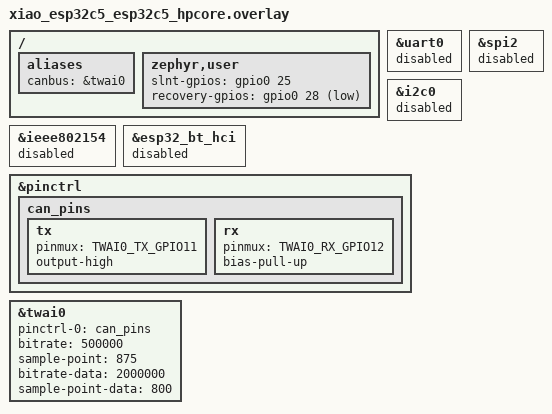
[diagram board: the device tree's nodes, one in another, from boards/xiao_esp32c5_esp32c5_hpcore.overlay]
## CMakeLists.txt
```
cmake_minimum_required(VERSION 3.20.0)
find_package(Zephyr REQUIRED HINTS $ENV{ZEPHYR_BASE})
project(wireless_can)
if(NOT EXISTS ${CMAKE_CURRENT_SOURCE_DIR}/credentials/device_credentials.h)
  message(FATAL_ERROR "Run tools/provision.py before building; there are no universal credentials")
endif()
target_include_directories(app PRIVATE credentials src)
target_sources(app PRIVATE src/main.c src/wire.c src/capture.c src/network.c src/wifi_config.c)
```

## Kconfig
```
mainmenu "Wireless CAN tool"
source "Kconfig.zephyr"
config WCAN_RX_DEPTH
    int "Internal RAM receive records"
    default 128
    range 16 1024
config WCAN_SLNT
    bool "GPIO25 connected to CAN Pal SLNT"
    default y
config WCAN_TX_EVENT_DEPTH
    int "TX outcome queue depth"
    default 32
    range 4 128
```

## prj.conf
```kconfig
CONFIG_GPIO=y
CONFIG_CAN=y
CONFIG_CAN_STATS=y
CONFIG_STATS=y
CONFIG_CAN_FD_MODE=y
CONFIG_CAN_ACCEPT_RTR=y
CONFIG_CAN_MANUAL_RECOVERY_MODE=y
CONFIG_CAN_RX_TIMESTAMP=n
CONFIG_WIFI=y
CONFIG_NETWORKING=y
CONFIG_NET_IPV4=y
CONFIG_NET_IPV6=n
CONFIG_NET_TCP=y
CONFIG_NET_UDP=y
CONFIG_NET_DHCPV4=y
CONFIG_NET_DHCPV4_SERVER=y
CONFIG_NET_MGMT=y
CONFIG_NET_MGMT_EVENT=y
CONFIG_NET_SOCKETS=y
CONFIG_NET_SOCKETS_SOCKOPT_TLS=y
CONFIG_NET_SOCKETS_TLS_MAX_CONTEXTS=2
CONFIG_NET_HOSTNAME_ENABLE=y
CONFIG_NET_HOSTNAME_DYNAMIC=y
CONFIG_NET_HOSTNAME="can-tool"
CONFIG_DNS_SD=y
CONFIG_MDNS_RESPONDER=y
CONFIG_MDNS_RESPONDER_DNS_SD=y
CONFIG_NET_BUF_RX_COUNT=32
CONFIG_NET_BUF_TX_COUNT=32
CONFIG_NET_PKT_RX_COUNT=16
CONFIG_NET_PKT_TX_COUNT=16
CONFIG_NET_MAX_CONTEXTS=10
CONFIG_MBEDTLS=y
CONFIG_MBEDTLS_PEM_PARSE_C=y
CONFIG_MBEDTLS_ENABLE_HEAP=y
CONFIG_MBEDTLS_HEAP_SIZE=60000
CONFIG_MBEDTLS_SSL_IN_CONTENT_LEN=4096
CONFIG_MBEDTLS_SSL_OUT_CONTENT_LEN=4096
CONFIG_MBEDTLS_CIPHERSUITE_TLS_ECDHE_ECDSA_WITH_AES_128_GCM_SHA256=y
CONFIG_TLS_CREDENTIALS=y
CONFIG_SETTINGS=y
CONFIG_SETTINGS_NVS=y
CONFIG_NVS=y
CONFIG_FLASH=y
CONFIG_FLASH_MAP=y
CONFIG_FLASH_PAGE_LAYOUT=y
CONFIG_ENTROPY_GENERATOR=y
CONFIG_TEST_RANDOM_GENERATOR=n
CONFIG_MAIN_STACK_SIZE=8192
CONFIG_SYSTEM_WORKQUEUE_STACK_SIZE=4096
CONFIG_HEAP_MEM_POOL_SIZE=56000
CONFIG_LOG=y
CONFIG_LOG_DEFAULT_LEVEL=2
CONFIG_REBOOT=y
CONFIG_ESP_SPIRAM=n

CONFIG_STACK_SENTINEL=y
```

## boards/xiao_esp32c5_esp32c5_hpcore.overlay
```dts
#include <zephyr/dt-bindings/pinctrl/esp32c5-pinctrl.h>
/ {
    aliases { canbus = &twai0; };
    zephyr,user { slnt-gpios = <&gpio0 25 GPIO_ACTIVE_HIGH>; recovery-gpios = <&gpio0 28 (GPIO_ACTIVE_LOW | GPIO_PULL_UP)>; };
};
&uart0 { status = "disabled"; };
&spi2 { status = "disabled"; };
&i2c0 { status = "disabled"; };
&ieee802154 { status = "disabled"; };
&esp32_bt_hci { status = "disabled"; };
&pinctrl {
    can_pins: can_pins {
        tx { pinmux = <TWAI0_TX_GPIO11>; output-high; };
        rx { pinmux = <TWAI0_RX_GPIO12>; bias-pull-up; };
    };
};
&twai0 { status = "okay"; pinctrl-0 = <&can_pins>; pinctrl-names = "default"; bitrate = <500000>; sample-point = <875>; bitrate-data = <2000000>; sample-point-data = <800>; };
```

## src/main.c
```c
#include "app.h"
#include "device_credentials.h"
#include <errno.h>
#include <stdio.h>
#include <string.h>
#include <zephyr/net/dns_sd.h>
#include <zephyr/net/socket.h>
#include <zephyr/net/tls_credentials.h>
#include <zephyr/random/random.h>
#include <zephyr/sys/reboot.h>

uint64_t boot_session;
DNS_SD_REGISTER_TCP_SERVICE(wcan, ap_ssid, "_wcan", "local", DNS_SD_EMPTY_TXT, 7443);
static uint8_t input[W_HEADER + W_MAX], output[W_HEADER + W_MAX];
static char response[2048];
static int send_packet(int fd, uint8_t kind, uint32_t request, const void *data, size_t len) {
    if (len > W_MAX)
        return -EMSGSIZE;
    struct w_header h = {kind, len, request, boot_session};
    w_header_encode(output, &h);
    memcpy(output + W_HEADER, data, len);
    size_t sent = 0;
    int64_t deadline = k_uptime_get() + 750;
    while (sent < len + W_HEADER && k_uptime_get() < deadline) {
        int n = zsock_send(fd, output + sent, len + W_HEADER - sent, 0);
        if (n <= 0)
            return -EIO;
        sent += n;
    }
    return sent == len + W_HEADER ? 0 : -ETIMEDOUT;
}
static void info_json(char *buf, size_t size) {
    int n =
        snprintf(buf, size,
                 "{\"ok\":true,\"firmware\":\"0.1.0-zephyr\",\"protocol\":1,"
                 "\"device\":\"%s\",\"session\":%llu,\"wifi_mode\":\"%s\","
                 "\"wifi_provision_version\":2,\"wifi_error\":%d,\"lease_ms\":3000,\"channels\":1,",
                 device_id, (unsigned long long)boot_session, network_mode(), network_error());
    n += capture_status(buf + n, size - n);
    if ((size_t)n + 2 < size) {
        buf[n++] = ',';
        n += network_status(buf + n, size - n);
    }
    if ((size_t)n + 2 < size) {
        buf[n++] = '}';
        buf[n] = 0;
    }
}
static void discard_queue(void) {
    struct w_frame f;
    unsigned n = 0;
    while (!k_msgq_get(&rx_queue, &f, K_NO_WAIT))
        n++;
    capture_discard(n);
    capture_discard_tx(k_msgq_num_used_get(&tx_events));
    k_msgq_purge(&tx_events);
}
static int command(const struct w_header *h, const uint8_t *p, bool *reboot) {
    int err = 0;
    switch (h->kind) {
    case 1:
    case 2:
    case 9:
        if (h->length)
            err = -EINVAL;
        break;
    case 3: {
        if (h->length != 14 || p[0] > 1 || p[1] > 1) {
            err = -EINVAL;
            break;
        }
        struct capture_config c = {.fd = p[0],
                                   .active = p[1],
                                   .bitrate = r32(p + 2),
                                   .sp = r16(p + 6),
                                   .data_bitrate = r32(p + 8),
                                   .data_sp = r16(p + 12)};
        err = capture_configure(&c);
        discard_queue();
        break;
    }
    case 4:
        if (h->length)
            err = -EINVAL;
        else
            err = capture_start();
        break;
    case 5:
    case 7:
        if (h->length)
            err = -EINVAL;
        else
            capture_stop();
        break;
    case 6: {
        if (h->length < 16 || h->length > 80 || p[15] || p[14] > 64 || h->length != 16U + p[14]) {
            err = -EINVAL;
            break;
        }
        struct w_frame f = {.id = r32(p + 8), .flags = p[12], .dlc = p[13], .len = p[14]};
        memcpy(f.data, p + 16, f.len);
        err = capture_tx(&f, r32(p), r32(p + 4), h->request);
        break;
    }
    case 8:
        err = network_provision(p, h->length);
        *reboot = !err;
        break;
    default:
        err = -ENOTSUP;
    }
    if (err)
        snprintf(response, sizeof(response),
                 "{\"ok\":false,\"error\":\"command rejected\",\"code\":%d}", err);
    else if (h->kind == 1 || h->kind == 2 || h->kind == 3)
        info_json(response, sizeof(response));
    else
        snprintf(response, sizeof(response), "{\"ok\":true,\"request\":%u,\"state\":\"%s\"}",
                 h->request, h->kind == 6 ? "accepted" : "applied");
    return err;
}
static void serve(int fd) {
    bool hello = false, reboot = false;
    size_t used = 0;
    uint32_t high_request = 0;
    int64_t partial_since = 0, last_status = 0, last_command = k_uptime_get();
    struct {
        uint32_t id;
        uint8_t kind;
        uint32_t len;
        uint8_t payload[96];
        char reply[2048];
    } cache = {0};
    capture_stop();
    discard_queue();
    while (1) {
        if (k_uptime_get() - last_command > 3000)
            break;
        struct zsock_pollfd poll = {.fd = fd, .events = ZSOCK_POLLIN};
        /* Avoid a fixed 10 ms batching ceiling when records are already waiting.
         * Still block briefly so lower-priority lease/TX work can run. */
        int timeout_ms =
            (k_msgq_num_used_get(&rx_queue) || k_msgq_num_used_get(&tx_events)) ? 1 : 10;
        int ready = zsock_poll(&poll, 1, timeout_ms);
        if (ready < 0 || (poll.revents & (ZSOCK_POLLERR | ZSOCK_POLLHUP | ZSOCK_POLLNVAL)))
            break;
        if (ready > 0 && (poll.revents & ZSOCK_POLLIN)) {
            int n = zsock_recv(fd, input + used, sizeof(input) - used, 0);
            if (n <= 0)
                break;
            if (!used)
                partial_since = k_uptime_get();
            used += n;
        }
        while (used >= W_HEADER) {
            struct w_header h;
            if (w_parse(input, &h) || !h.request)
                goto done;
            if (used < W_HEADER + h.length)
                break;
            const uint8_t *payload = input + W_HEADER;
            if ((!hello && (h.kind != 1 || h.session)) || (hello && h.session != boot_session))
                goto done;
            if (h.request <= high_request) {
                if (h.request == cache.id && h.kind == cache.kind && h.length == cache.len &&
                    h.length <= sizeof(cache.payload) && !memcmp(cache.payload, payload, h.length))
                    strcpy(response, cache.reply);
                else
                    snprintf(response, sizeof(response),
                             "{\"ok\":false,\"error\":\"duplicate or stale request; not "
                             "executed\"}");
            } else {
                high_request = h.request;
                if (h.kind == 1 && hello)
                    goto done;
                command(&h, payload, &reboot);
                if (h.kind == 1)
                    hello = true;
                cache.id = h.request;
                cache.kind = h.kind;
                cache.len = h.length;
                if (h.length <= sizeof(cache.payload))
                    memcpy(cache.payload, payload, h.length);
                strcpy(cache.reply, response);
            }
            last_command = k_uptime_get();
            capture_lease();
            if (send_packet(fd, 128, h.request, response, strlen(response)))
                goto done;
            size_t consumed = W_HEADER + h.length;
            used -= consumed;
            memmove(input, input + consumed, used);
            partial_since = k_uptime_get();
            if (reboot) {
                capture_stop();
                k_sleep(K_MSEC(100));
                sys_reboot(SYS_REBOOT_COLD);
            }
        }
        if (used && k_uptime_get() - partial_since > 2000)
            break;
        if (!hello)
            continue;
        uint8_t batch[16 * 88];
        size_t len = 0;
        unsigned frames = 0;
        struct w_frame f;
        while (frames < 16 && !k_msgq_get(&rx_queue, &f, K_NO_WAIT)) {
            len += w_encode(batch + len, &f);
            frames++;
        }
        if (frames && send_packet(fd, 130, 0, batch, len)) {
            capture_discard(frames);
            break;
        }
        struct tx_event event;
        while (!k_msgq_get(&tx_events, &event, K_NO_WAIT)) {
            snprintf(response, sizeof(response),
                     "{\"request\":%u,\"completed\":%u,\"state\":\"%s\",\"error\":%d,"
                     "\"terminal\":%s}",
                     event.request, event.completed,
                     event.error == -EINPROGRESS ? "indeterminate"
                     : event.error == -ECANCELED ? "cancelled"
                     : event.error               ? "failed"
                                                 : "completed",
                     event.error, event.terminal ? "true" : "false");
            if (send_packet(fd, 131, event.request, response, strlen(response))) {
                capture_discard_tx(1);
                goto done;
            }
        }
        if (k_uptime_get() - last_status >= 1000) {
            info_json(response, sizeof(response));
            if (send_packet(fd, 129, 0, response, strlen(response)))
                break;
            last_status = k_uptime_get();
        }
    }
done:
    capture_stop();
    discard_queue();
    memset(input, 0, sizeof(input));
    memset(&cache, 0, sizeof(cache));
}
void server_run(void) {
    sec_tag_t tag = 1;
    int verify = TLS_PEER_VERIFY_REQUIRED;
    if (tls_credential_add(tag, TLS_CREDENTIAL_CA_CERTIFICATE, ca_pem, sizeof(ca_pem)) ||
        tls_credential_add(tag, TLS_CREDENTIAL_PUBLIC_CERTIFICATE, server_pem,
                           sizeof(server_pem)) ||
        tls_credential_add(tag, TLS_CREDENTIAL_PRIVATE_KEY, server_key_pem, sizeof(server_key_pem)))
        return;
    int fd = zsock_socket(AF_INET, SOCK_STREAM, IPPROTO_TLS_1_2);
    if (fd < 0)
        return;
    if (zsock_setsockopt(fd, SOL_TLS, TLS_SEC_TAG_LIST, &tag, sizeof(tag)) ||
        zsock_setsockopt(fd, SOL_TLS, TLS_PEER_VERIFY, &verify, sizeof(verify))) {
        zsock_close(fd);
        return;
    }
    struct timeval timeout = {.tv_sec = 1};
    zsock_setsockopt(fd, SOL_SOCKET, SO_RCVTIMEO, &timeout, sizeof(timeout));
    zsock_setsockopt(fd, SOL_SOCKET, SO_SNDTIMEO, &timeout, sizeof(timeout));
    struct sockaddr_in address = {
        .sin_family = AF_INET, .sin_port = htons(7443), .sin_addr.s_addr = htonl(INADDR_ANY)};
    if (zsock_bind(fd, (struct sockaddr *)&address, sizeof(address)) || zsock_listen(fd, 1)) {
        zsock_close(fd);
        return;
    }
    while (1) {
        int client = zsock_accept(fd, NULL, NULL);
        if (client < 0) {
            k_sleep(K_MSEC(100));
            continue;
        }
        zsock_setsockopt(client, SOL_SOCKET, SO_RCVTIMEO, &timeout, sizeof(timeout));
        zsock_setsockopt(client, SOL_SOCKET, SO_SNDTIMEO, &timeout, sizeof(timeout));
        serve(client);
        zsock_close(client);
    }
}
int main(void) {
    if (sys_csrand_get(&boot_session, sizeof(boot_session)))
        return -EIO;
    if (!boot_session)
        boot_session = 1;
    int err = capture_init();
    if (err) {
        printk("CAN initialization failed: %d\n", err);
        return err;
    }
    err = network_init();
    if (err) {
        printk("Wi-Fi initialization failed: %d\n", err);
        return err;
    }
    printk("Wireless CAN %s: TLS TCP 7443; AP address 192.168.4.1; capture "
           "stopped\n",
           device_id);
    server_run();
    capture_stop();
    printk("TLS server failed; transmission disabled\n");
    return -EIO;
}
```

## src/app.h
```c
#pragma once
#include "wire.h"
#include <zephyr/kernel.h>
struct capture_config {
    bool fd, active;
    uint32_t bitrate, data_bitrate;
    uint16_t sp, data_sp;
};
struct tx_event {
    uint32_t request, completed;
    int error;
    bool terminal;
};
extern struct k_msgq rx_queue, tx_events;
extern struct capture_config applied;
extern uint64_t boot_session;
int capture_init(void);
int capture_configure(const struct capture_config *cfg);
int capture_start(void);
void capture_stop(void);
void capture_lease(void);
int capture_tx(const struct w_frame *f, uint32_t interval, uint32_t count, uint32_t request);
void capture_cancel(void);
void capture_discard(unsigned n);
void capture_discard_tx(unsigned n);
size_t capture_status(char *buffer, size_t size);
int network_init(void);
int network_provision(const uint8_t *p, size_t n);
const char *network_mode(void);
int network_error(void);
size_t network_status(char *out, size_t size);
void server_run(void);
```

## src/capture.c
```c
#include "app.h"
#include <stdio.h>
#include <string.h>
#include <zephyr/drivers/can.h>
#include <zephyr/drivers/gpio.h>
#include <zephyr/sys/atomic.h>

static const struct device *can = DEVICE_DT_GET(DT_ALIAS(canbus));
static const struct gpio_dt_spec slnt = GPIO_DT_SPEC_GET(DT_PATH(zephyr_user), slnt_gpios);
K_MSGQ_DEFINE(rx_queue, sizeof(struct w_frame), CONFIG_WCAN_RX_DEPTH, 4);
K_MSGQ_DEFINE(tx_events, sizeof(struct tx_event), CONFIG_WCAN_TX_EVENT_DEPTH, 4);
K_MUTEX_DEFINE(control);
static struct k_spinlock stats_lock;
static uint64_t received, enqueued, drops, discards, sequence;
static uint32_t highwater;
static atomic_t tx_event_drops;
static bool running, scheduled, inflight, configured;
static uint32_t tx_request, remaining, completed, interval_ms;
static int64_t next_send, lease_deadline, tx_deadline;
static struct can_frame outgoing;
static atomic_t completion_ready, completion_error;
struct capture_config applied = {
    .bitrate = 500000, .sp = 875, .data_bitrate = 2000000, .data_sp = 800};

static void silent(bool yes) {
    if (IS_ENABLED(CONFIG_WCAN_SLNT))
        gpio_pin_set_dt(&slnt, yes);
}
static void event(int error, bool terminal) {
    struct tx_event e = {tx_request, completed, error, terminal};
    if (k_msgq_put(&tx_events, &e, K_NO_WAIT))
        atomic_inc(&tx_event_drops);
}
static void rx(const struct device *dev, struct can_frame *f, void *arg) {
    ARG_UNUSED(dev);
    ARG_UNUSED(arg);
    struct w_frame rec = {
        .us = k_ticks_to_us_floor64(k_uptime_ticks()), .id = f->id, .dlc = f->dlc};
    rec.flags = ((f->flags & CAN_FRAME_IDE) ? W_EXT : 0) | ((f->flags & CAN_FRAME_FDF) ? W_FD : 0) |
                ((f->flags & CAN_FRAME_BRS) ? W_BRS : 0) |
                ((f->flags & CAN_FRAME_ESI) ? W_ESI : 0) | ((f->flags & CAN_FRAME_RTR) ? W_RTR : 0);
    rec.len = (rec.flags & W_RTR) ? 0 : ((rec.flags & W_FD) ? w_length(rec.dlc) : MIN(rec.dlc, 8));
    if (rec.len > 64)
        return;
    memcpy(rec.data, f->data, rec.len);
    k_spinlock_key_t key = k_spin_lock(&stats_lock);
    rec.seq = ++sequence;
    received++;
    if (k_msgq_put(&rx_queue, &rec, K_NO_WAIT))
        drops++;
    else {
        enqueued++;
        highwater = MAX(highwater, k_msgq_num_used_get(&rx_queue));
    }
    k_spin_unlock(&stats_lock, key);
}
static void tx_done(const struct device *dev, int error, void *arg) {
    ARG_UNUSED(dev);
    ARG_UNUSED(arg);
    atomic_set(&completion_error, error);
    atomic_set(&completion_ready, 1);
}
static void stop_locked(void) {
    silent(true);
    bool uncertain = inflight;
    if (running)
        can_stop(can); /* pinned driver aborts hardware TX buffers */
    running = false;
    if (scheduled || inflight)
        event(uncertain ? -EINPROGRESS : -ECANCELED, true);
    scheduled = false;
    inflight = false;
    remaining = 0;
    atomic_clear(&completion_ready);
    applied.active = false;
}
void capture_stop(void) {
    k_mutex_lock(&control, K_FOREVER);
    stop_locked();
    k_mutex_unlock(&control);
}
void capture_cancel(void) { capture_stop(); }
void capture_lease(void) {
    k_mutex_lock(&control, K_FOREVER);
    lease_deadline = k_uptime_get() + 3000;
    k_mutex_unlock(&control);
}
void capture_discard_tx(unsigned n) {
    while (n--)
        atomic_inc(&tx_event_drops);
}
void capture_discard(unsigned n) {
    k_spinlock_key_t key = k_spin_lock(&stats_lock);
    discards += n;
    k_spin_unlock(&stats_lock, key);
}
static int timing(uint32_t rate, uint16_t sp, bool data, struct can_timing *t) {
    uint32_t clock;
    if (sp < 500 || sp > 950 || rate < 10000 || rate > (data ? 5000000 : 1000000))
        return -EINVAL;
    int err = data ? can_calc_timing_data(can, t, rate, sp) : can_calc_timing(can, t, rate, sp);
    if (err != 0)
        return -ERANGE; /* reject sample point approximation */
    err = can_get_core_clock(can, &clock);
    uint32_t quanta = 1 + t->prop_seg + t->phase_seg1 + t->phase_seg2;
    if (err || clock != (uint64_t)rate * t->prescaler * quanta ||
        (1 + t->prop_seg + t->phase_seg1) * 1000U != sp * quanta)
        return -ERANGE;
    return 0;
}
int capture_configure(const struct capture_config *cfg) {
    k_mutex_lock(&control, K_FOREVER);
    stop_locked();
    configured = false;
    struct can_timing nominal = {0}, data = {0};
    int err = timing(cfg->bitrate, cfg->sp, false, &nominal);
    if (!err && cfg->fd)
        err = timing(cfg->data_bitrate, cfg->data_sp, true, &data);
    if (!err)
        err = can_set_mode(can, (cfg->active ? 0 : CAN_MODE_LISTENONLY) |
                                    (cfg->fd ? CAN_MODE_FD : 0) | CAN_MODE_MANUAL_RECOVERY |
                                    CAN_MODE_ONE_SHOT);
    if (!err)
        err = can_set_timing(can, &nominal);
    if (!err && cfg->fd)
        err = can_set_timing_data(can, &data);
    if (!err) {
        applied = *cfg;
        configured = true;
    }
    k_mutex_unlock(&control);
    return err;
}
int capture_start(void) {
    k_mutex_lock(&control, K_FOREVER);
    int err = running ? -EALREADY
                      : (!configured
                             ? -EINVAL
                             : can_set_mode(can, (applied.active ? 0 : CAN_MODE_LISTENONLY) |
                                                     (applied.fd ? CAN_MODE_FD : 0) |
                                                     CAN_MODE_MANUAL_RECOVERY | CAN_MODE_ONE_SHOT));
    if (!err)
        err = can_start(can);
    if (!err) {
        running = true;
        silent(!applied.active);
        lease_deadline = k_uptime_get() + 3000;
    }
    k_mutex_unlock(&control);
    return err;
}
int capture_tx(const struct w_frame *f, uint32_t interval, uint32_t count, uint32_t request) {
    if (w_validate(f, true) || !count || count > 10000 || interval > 60000 ||
        (count > 1 && interval < 10))
        return -EINVAL;
    k_mutex_lock(&control, K_FOREVER);
    int err = 0;
    if (!running || !applied.active)
        err = -EPERM;
    else if (scheduled || inflight)
        err = -EBUSY;
    else if ((f->flags & W_FD) && !applied.fd)
        err = -EINVAL;
    else {
        outgoing = (struct can_frame){.id = f->id,
                                      .dlc = f->dlc,
                                      .flags = ((f->flags & W_EXT) ? CAN_FRAME_IDE : 0) |
                                               ((f->flags & W_FD) ? CAN_FRAME_FDF : 0) |
                                               ((f->flags & W_BRS) ? CAN_FRAME_BRS : 0) |
                                               ((f->flags & W_RTR) ? CAN_FRAME_RTR : 0)};
        memcpy(outgoing.data, f->data, f->len);
        tx_request = request;
        remaining = count;
        completed = 0;
        interval_ms = interval;
        next_send = k_uptime_get();
        scheduled = true;
    }
    k_mutex_unlock(&control);
    return err;
}
static void scheduler_tick(void) {
    k_mutex_lock(&control, K_FOREVER);
    int64_t now = k_uptime_get();
    if (running && now > lease_deadline)
        stop_locked();
    if (inflight && atomic_cas(&completion_ready, 1, 0)) {
        int err = atomic_get(&completion_error);
        inflight = false;
        if (!err)
            completed++;
        event(err, err || !remaining);
        if (err || !remaining)
            scheduled = false;
    }
    if (inflight && now > tx_deadline)
        stop_locked();
    if (scheduled && !inflight && now >= next_send) {
        remaining--;
        inflight = true;
        tx_deadline = now + 1000;
        int err = can_send(can, &outgoing, K_NO_WAIT, tx_done, NULL);
        if (err) {
            inflight = false;
            scheduled = false;
            event(err, true);
        }
        next_send = now + interval_ms; /* no catch-up burst */
    }
    k_mutex_unlock(&control);
}
static void scheduler(void *a, void *b, void *c) {
    ARG_UNUSED(a);
    ARG_UNUSED(b);
    ARG_UNUSED(c);
    while (1) {
        scheduler_tick();
        k_sleep(K_MSEC(2));
    }
}
K_THREAD_DEFINE(tx_scheduler, 2048, scheduler, NULL, NULL, NULL, 5, 0, 0);
int capture_init(void) {
    if (!device_is_ready(can))
        return -ENODEV;
    if (IS_ENABLED(CONFIG_WCAN_SLNT)) {
        if (!gpio_is_ready_dt(&slnt))
            return -ENODEV;
        int err = gpio_pin_configure_dt(&slnt, GPIO_OUTPUT_ACTIVE);
        if (err)
            return err;
    }
    struct can_filter standard = {.id = 0, .mask = 0},
                      extended = {.id = 0, .mask = 0, .flags = CAN_FILTER_IDE};
    int s = can_add_rx_filter(can, rx, NULL, &standard),
        e = can_add_rx_filter(can, rx, NULL, &extended);
    if (s < 0 || e < 0)
        return -ENOSPC;
    struct capture_config defaults = applied;
    return capture_configure(&defaults);
}
size_t capture_status(char *out, size_t size) {
    enum can_state state;
    struct can_bus_err_cnt counts = {0};
    k_mutex_lock(&control, K_FOREVER);
    int err = can_get_state(can, &state, &counts);
    k_spinlock_key_t key = k_spin_lock(&stats_lock);
    uint64_t r = received, e = enqueued, d = drops, t = discards, s = sequence;
    uint32_t high = highwater;
    k_spin_unlock(&stats_lock, key);
    int n = snprintf(out, size,
                     "\"capture\":%s,\"active\":%s,\"hardware_silent\":%s,\"fd\":%s,"
                     "\"bitrate\":%u,\"sample_point\":%u,\"data_bitrate\":%u,\"data_sample_"
                     "point\":%u,\"received\":%llu,\"enqueued\":%llu,\"queue_drops\":%llu,"
                     "\"transport_discards\":%llu,\"queue_used\":%u,\"queue_highwater\":%u,"
                     "\"last_sequence\":%llu,\"controller_state\":%d,\"rx_errors\":%u,\"tx_"
                     "errors\":%u,\"state_read_error\":%d,\"hardware_rx_losses\":null,\"bus_"
                     "error_events\":null,\"tx_event_discards\":%ld,\"hardware_filters\":null,"
                     "\"capture_filter\":\"all_standard_and_extended\",\"timestamp_method\":"
                     "\"callback_kernel_ticks_us\"",
                     running ? "true" : "false", applied.active ? "true" : "false",
                     IS_ENABLED(CONFIG_WCAN_SLNT) ? "true" : "false", applied.fd ? "true" : "false",
                     applied.bitrate, applied.sp, applied.data_bitrate, applied.data_sp,
                     (unsigned long long)r, (unsigned long long)e, (unsigned long long)d,
                     (unsigned long long)t, k_msgq_num_used_get(&rx_queue), high,
                     (unsigned long long)s, err ? -1 : state, counts.rx_err_cnt, counts.tx_err_cnt,
                     err, (long)atomic_get(&tx_event_drops));
    if (n > 0 && (size_t)n < size)
        n += snprintf(out + n, size - n,
                      ",\"configured\":%s,\"timestamp_resolution_us\":%u,\"bus_bit_errors\":%"
                      "u,\"bus_stuff_errors\":%u,\"bus_form_errors\":%u,\"bus_ack_errors\":%"
                      "u,\"bus_crc_errors\":null",
                      configured ? "true" : "false", 1000000 / CONFIG_SYS_CLOCK_TICKS_PER_SEC,
                      can_stats_get_bit_errors(can), can_stats_get_stuff_errors(can),
                      can_stats_get_form_errors(can), can_stats_get_ack_errors(can));
    k_mutex_unlock(&control);
    return n < 0 ? 0 : MIN((size_t)n, size - 1);
}
```

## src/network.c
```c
#include "app.h"
#include "wifi_config.h"
#include <soc.h>
#include <esp_wifi.h>
#include "device_credentials.h"
#include <errno.h>
#include <stdio.h>
#include <string.h>
#include <zephyr/drivers/gpio.h>
#include <zephyr/net/net_if.h>
#include <zephyr/net/dhcpv4.h>
#include <zephyr/net/dhcpv4_server.h>
#include <zephyr/net/hostname.h>
#include <zephyr/net/net_ip.h>
#include <zephyr/net/wifi_mgmt.h>
#include <zephyr/settings/settings.h>
#include <zephyr/sys/atomic.h>
#include <zephyr/sys/reboot.h>

static struct wifi_saved saved;
static struct net_if *iface;
static struct net_mgmt_event_callback wifi_cb;
static atomic_t last_error, connected, ready, radio_ready;
static struct wifi_connect_req_params params;
static const struct gpio_dt_spec recovery = GPIO_DT_SPEC_GET(DT_PATH(zephyr_user), recovery_gpios);
static int load(const char *name, size_t len, settings_read_cb read, void *arg) {
    if (strcmp(name, "wifi") || (len != sizeof(saved) && len != offsetof(struct wifi_saved, band)))
        return -ENOENT;
    struct wifi_saved candidate = {0};
    int n = read(arg, &candidate, len);
    if (n != len || wifi_saved_validate(&candidate))
        return -EINVAL;
    saved = candidate;
    return 0;
}
SETTINGS_STATIC_HANDLER_DEFINE(wcan, "wcan", NULL, load, NULL, NULL);
static void wifi_event(struct net_mgmt_event_callback *cb, uint64_t event, struct net_if *i) {
    ARG_UNUSED(i);
    if (event == NET_EVENT_WIFI_CONNECT_RESULT || event == NET_EVENT_WIFI_AP_ENABLE_RESULT) {
        const struct wifi_status *status = cb->info;
        atomic_set(&last_error, status ? status->status : -EIO);
        atomic_set(&connected, status && status->status == 0);
    } else if (event == NET_EVENT_WIFI_DISCONNECT_RESULT) {
        atomic_set(&connected, 0);
        atomic_set(&last_error, -ENETDOWN);
        /* Lease task independently bounds any application transmissions. */
    }
}
const char *network_mode(void) { return saved.station ? "station" : "ap"; }
int network_error(void) { return atomic_get(&last_error); }
int network_provision(const uint8_t *p, size_t n) {
    struct wifi_saved candidate;
    int err = wifi_payload_parse(p, n, &candidate);
    if (err)
        return err;
    capture_stop();
    return settings_save_one("wcan/wifi", &candidate, sizeof(candidate));
}
static void recovery_thread(void *a, void *b, void *c) {
    ARG_UNUSED(a);
    ARG_UNUSED(b);
    ARG_UNUSED(c);
    bool released = false;
    int64_t pressed = 0, last_retry = 0;
    while (!atomic_get(&ready))
        k_sleep(K_MSEC(100));
    k_sleep(K_SECONDS(5)); /* never use a held boot strap as an application action */
    while (1) {
        int level = gpio_pin_get_dt(&recovery);
        if (level == 0) {
            released = true;
            pressed = 0;
        }
        if (level > 0 && released) {
            if (!pressed)
                pressed = k_uptime_get();
            if (k_uptime_get() - pressed >= 3000) {
                capture_stop();
                struct wifi_saved ap = {0};
                if (settings_save_one("wcan/wifi", &ap, sizeof(ap)) == 0)
                    sys_reboot(SYS_REBOOT_COLD);
            }
        }
        if (atomic_get(&radio_ready) && saved.station && !atomic_get(&connected) &&
            k_uptime_get() - last_retry > 15000) {
            capture_stop();
            int err = net_mgmt(NET_REQUEST_WIFI_CONNECT, iface, &params, sizeof(params));
            if (err)
                atomic_set(&last_error, err);
            last_retry = k_uptime_get();
        }
        k_sleep(K_MSEC(100));
    }
}
K_THREAD_DEFINE(recovery_task, 2048, recovery_thread, NULL, NULL, NULL, 7, 0, 0);
int network_init(void) {
    int err = settings_subsys_init();
    if (err)
        return err;
    err = settings_load_subtree("wcan");
    if (err)
        return err;
    if (!gpio_is_ready_dt(&recovery))
        return -ENODEV;
    err = gpio_pin_configure_dt(&recovery, GPIO_INPUT);
    if (err)
        return err;
    net_mgmt_init_event_callback(&wifi_cb, wifi_event,
                                 NET_EVENT_WIFI_CONNECT_RESULT | NET_EVENT_WIFI_DISCONNECT_RESULT |
                                     NET_EVENT_WIFI_AP_ENABLE_RESULT);
    net_mgmt_add_event_callback(&wifi_cb);
    char host[32];
    snprintf(host, sizeof(host), "can-%s", device_id);
    net_hostname_set(host, strlen(host));
    iface = net_if_get_default();
    if (!iface)
        return -ENODEV;
    params = (struct wifi_connect_req_params){
        .ssid = (const uint8_t *)(saved.station ? saved.ssid : ap_ssid),
        .psk = (const uint8_t *)(saved.station ? saved.password : ap_password),
        .security = WIFI_SECURITY_TYPE_PSK,
        .channel = saved.station ? WIFI_CHANNEL_ANY
                                 : (saved.channel ? saved.channel : (saved.band ? 36 : 6)),
        .band = saved.band ? WIFI_FREQ_BAND_5_GHZ : WIFI_FREQ_BAND_2_4_GHZ,
        .mfp = WIFI_MFP_OPTIONAL,
        .timeout = 10};
    params.ssid_length = strlen((const char *)params.ssid);
    params.psk_length = strlen((const char *)params.psk);
    /* The pinned Zephyr ESP32 driver ignores params.band. Apply the HAL band
     * explicitly before association/AP startup; its device init already started
     * Wi-Fi in NULL mode. Never silently fall back to the other band. */
    err = esp_wifi_set_country_code(saved.country[0] ? saved.country : "01", false);
    if (!err)
        err = esp_wifi_set_band_mode(saved.band ? WIFI_BAND_MODE_5G_ONLY : WIFI_BAND_MODE_2G_ONLY);
    if (err) {
        atomic_set(&last_error, -err);
        atomic_set(&ready, 1); /* physical recovery must still work */
        return 0;
    }
    atomic_set(&radio_ready, 1);
    if (saved.station) {
        net_dhcpv4_start(iface);
        err = net_mgmt(NET_REQUEST_WIFI_CONNECT, iface, &params, sizeof(params));
    } else {
        struct net_in_addr ip, mask, pool;
        net_addr_pton(NET_AF_INET, "192.168.4.1", &ip);
        net_addr_pton(NET_AF_INET, "255.255.255.0", &mask);
        net_addr_pton(NET_AF_INET, "192.168.4.10", &pool);
        if (!net_if_ipv4_addr_add(iface, &ip, NET_ADDR_MANUAL, 0))
            return -EIO;
        net_if_ipv4_set_netmask_by_addr(iface, &ip, &mask);
        err = net_mgmt(NET_REQUEST_WIFI_AP_ENABLE, iface, &params, sizeof(params));
        if (!err)
            err = net_dhcpv4_server_start(iface, &pool);
    }
    atomic_set(&last_error, err);
    atomic_set(&ready, 1);
    return 0; /* failure remains observable; physical recovery remains available
               */
}

size_t network_status(char *out, size_t size) {
    char address[NET_IPV4_ADDR_LEN] = "unassigned";
    struct net_in_addr *ip = iface ? net_if_ipv4_get_global_addr(iface, NET_ADDR_PREFERRED) : NULL;
    if (ip)
        net_addr_ntop(NET_AF_INET, ip, address, sizeof(address));
    struct wifi_iface_status status = {0};
    bool up = atomic_get(&connected);
    bool known = up && !net_mgmt(NET_REQUEST_WIFI_IFACE_STATUS, iface, &status, sizeof(status));
    const char *band = known && status.band == WIFI_FREQ_BAND_5_GHZ     ? "\"5GHz\""
                       : known && status.band == WIFI_FREQ_BAND_2_4_GHZ ? "\"2.4GHz\""
                                                                        : "null";
    const char *phy = known && saved.station && status.link_mode == WIFI_6   ? "\"802.11ax\""
                      : known && saved.station && status.link_mode == WIFI_4 ? "\"802.11n\""
                                                                             : "null";
    int n = snprintf(out, size,
                     "\"wifi_connected\":%s,\"ip\":\"%s\",\"wifi_band_requested\":\"%s\","
                     "\"wifi_band\":%s,\"wifi_channel\":%u,\"wifi_phy\":%s,\"wifi_country\":\"%s\"",
                     up ? "true" : "false", address, saved.band ? "5GHz" : "2.4GHz", band,
                     known ? status.channel : 0, phy, saved.country[0] ? saved.country : "01");
    return n < 0 ? 0 : MIN((size_t)n, size - 1);
}
```

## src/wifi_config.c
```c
#include "wifi_config.h"
#include <errno.h>
#include <stdbool.h>
#include <string.h>
int wifi_saved_validate(const struct wifi_saved *c) {
    if (c->station > 1 || c->band > 1 || c->ssid[32] || c->password[63] || c->country[2])
        return -EINVAL;
    if (c->country[0]) {
        static const char countries[] =
            "AT AU BE BG BR CA CH CN CY CZ DE DK EE ES FI FR GB GR HK HR HU IE IN IS IT JP KR LI "
            "LT LU LV MT MX NL NO NZ PL PT RO SE SI SK TW US";
        bool found = false;
        for (size_t i = 0; i + 1 < sizeof(countries); i += 3)
            if (!memcmp(countries + i, c->country, 2))
                found = true;
        if (!found)
            return -ENOTSUP;
        if (c->country[0] < 'A' || c->country[0] > 'Z' || c->country[1] < 'A' ||
            c->country[1] > 'Z')
            return -EINVAL;
    } else if (c->country[1] || c->band) {
        return -EINVAL;
    }
    if (c->station && (!c->ssid[0] || strlen(c->password) < 8))
        return -EINVAL;
    if (!c->station && (c->ssid[0] || c->password[0]))
        return -EINVAL;
    if (c->station && c->channel)
        return -EINVAL; /* station scans selected band */
    if (c->channel &&
        (c->band ? !(c->channel == 36 || c->channel == 40 || c->channel == 44 || c->channel == 48)
                 : c->channel > 11))
        return -EINVAL; /* limited non-DFS AP channel set, still checked by HAL */
    return 0;
}
int wifi_payload_parse(const uint8_t *p, size_t n, struct wifi_saved *c) {
    if (n < 3)
        return -EINVAL;
    memset(c, 0, sizeof(*c));
    size_t offset = 3;
    c->station = p[0];
    if (p[0] & 0x80) {
        if (n < 7)
            return -EINVAL;
        c->station &= 0x7f;
        c->band = p[3];
        c->channel = p[4];
        memcpy(c->country, p + 5, 2);
        offset = 7;
    }
    if (p[1] > 32 || p[2] > 63 || n != offset + p[1] + p[2] || memchr(p + offset, 0, n - offset))
        return -EINVAL;
    memcpy(c->ssid, p + offset, p[1]);
    memcpy(c->password, p + offset + p[1], p[2]);
    return wifi_saved_validate(c);
}
```

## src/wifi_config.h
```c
#pragma once
#include <stddef.h>
#include <stdint.h>
struct wifi_saved {
    uint8_t station;
    char ssid[33];
    char password[64];
    uint8_t band;    /* 0: 2.4 GHz, 1: 5 GHz */
    uint8_t channel; /* zero: station scan or AP default */
    char country[3]; /* empty: factory world domain */
};
int wifi_saved_validate(const struct wifi_saved *cfg);
int wifi_payload_parse(const uint8_t *p, size_t n, struct wifi_saved *cfg);
```

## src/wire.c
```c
#include "wire.h"
#include <string.h>
uint16_t r16(const uint8_t *p) { return ((uint16_t)p[0] << 8) | p[1]; }
uint32_t r32(const uint8_t *p) { return ((uint32_t)r16(p) << 16) | r16(p + 2); }
uint64_t r64(const uint8_t *p) { return ((uint64_t)r32(p) << 32) | r32(p + 4); }
void w16(uint8_t *p, uint16_t v) {
    p[0] = v >> 8;
    p[1] = v;
}
void w32(uint8_t *p, uint32_t v) {
    w16(p, v >> 16);
    w16(p + 2, v);
}
void w64(uint8_t *p, uint64_t v) {
    w32(p, v >> 32);
    w32(p + 4, v);
}
uint8_t w_length(uint8_t d) {
    static const uint8_t l[] = {0, 1, 2, 3, 4, 5, 6, 7, 8, 12, 16, 20, 24, 32, 48, 64};
    return d < 16 ? l[d] : 255;
}
int w_parse(const uint8_t *p, struct w_header *h) {
    if (memcmp(p, "WCAN", 4) || p[4] != 1 || r16(p + 6) || r32(p + 8) > W_MAX || p[5] < 1 ||
        p[5] > 9)
        return -1;
    h->kind = p[5];
    h->length = r32(p + 8);
    h->request = r32(p + 12);
    h->session = r64(p + 16);
    return 0;
}
void w_header_encode(uint8_t *p, const struct w_header *h) {
    memcpy(p, "WCAN", 4);
    p[4] = 1;
    p[5] = h->kind;
    w16(p + 6, 0);
    w32(p + 8, h->length);
    w32(p + 12, h->request);
    w64(p + 16, h->session);
}
int w_validate(const struct w_frame *f, bool tx) {
    if (f->channel || f->flags & ~31 || f->dlc > 15 ||
        f->id > ((f->flags & W_EXT) ? 0x1fffffff : 0x7ff))
        return -1;
    if ((f->flags & W_FD) && (f->flags & W_RTR))
        return -1;
    if (!(f->flags & W_FD) && (f->flags & (W_BRS | W_ESI)))
        return -1;
    if (tx && ((f->flags & W_ESI) || (!(f->flags & W_FD) && f->dlc > 8)))
        return -1;
    uint8_t n =
        (f->flags & W_RTR) ? 0 : ((f->flags & W_FD) ? w_length(f->dlc) : (f->dlc < 8 ? f->dlc : 8));
    return n == f->len ? 0 : -1;
}
size_t w_encode(uint8_t *p, const struct w_frame *f) {
    w64(p, f->seq);
    w64(p + 8, f->us);
    w32(p + 16, f->id);
    p[20] = f->channel;
    p[21] = f->flags;
    p[22] = f->dlc;
    p[23] = f->len;
    memcpy(p + 24, f->data, f->len);
    return 24 + f->len;
}
```

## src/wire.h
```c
#pragma once
#include <stdbool.h>
#include <stddef.h>
#include <stdint.h>
#define W_HEADER 24
#define W_MAX 4096
#define W_EXT 1
#define W_FD 2
#define W_BRS 4
#define W_ESI 8
#define W_RTR 16
struct w_header {
    uint8_t kind;
    uint32_t length, request;
    uint64_t session;
};
struct w_frame {
    uint64_t seq, us;
    uint32_t id;
    uint8_t channel, flags, dlc, len, data[64];
};
uint16_t r16(const uint8_t *p);
uint32_t r32(const uint8_t *p);
uint64_t r64(const uint8_t *p);
void w16(uint8_t *p, uint16_t v);
void w32(uint8_t *p, uint32_t v);
void w64(uint8_t *p, uint64_t v);
int w_parse(const uint8_t *p, struct w_header *h);
void w_header_encode(uint8_t *p, const struct w_header *h);
int w_validate(const struct w_frame *f, bool tx);
size_t w_encode(uint8_t *p, const struct w_frame *f);
uint8_t w_length(uint8_t dlc);
```
